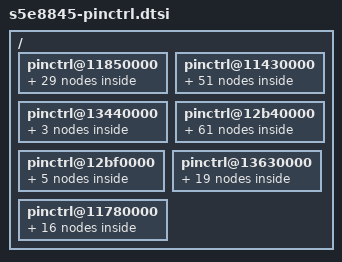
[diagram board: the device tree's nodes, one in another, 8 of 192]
/*
 * Samsung's S5E8845 SoC pin-mux and pin-config device tree source
 *
 * Copyright (c) 2023 Samsung Electronics Co., Ltd.
 *		http://www.samsung.com
 *
 * Samsung's S5E8845 SoC pin-mux and pin-config options are listed as device
 * tree nodes are listed in this file.
 *
 * This program is free software; you can redistribute it and/or modify
 * it under the terms of the GNU General Public License version 2 as
 * published by the Free Software Foundation.
*/

/ {
	/* ALIVE */
	pinctrl@11850000 {
		gpa0: gpa0 {
			gpio-controller;
			#gpio-cells = <2>;

			interrupt-controller;
			#interrupt-cells = <2>;
			interrupt-parent = <&gic>;
			interrupts = <GIC_SPI INTREQ__ALIVE_EINT0 IRQ_TYPE_LEVEL_HIGH>,
					<GIC_SPI INTREQ__ALIVE_EINT1 IRQ_TYPE_LEVEL_HIGH>,
					<GIC_SPI INTREQ__ALIVE_EINT2 IRQ_TYPE_LEVEL_HIGH>,
					<GIC_SPI INTREQ__ALIVE_EINT3 IRQ_TYPE_LEVEL_HIGH>,
					<GIC_SPI INTREQ__ALIVE_EINT4 IRQ_TYPE_LEVEL_HIGH>,
					<GIC_SPI INTREQ__ALIVE_EINT5 IRQ_TYPE_LEVEL_HIGH>,
					<GIC_SPI INTREQ__ALIVE_EINT6 IRQ_TYPE_LEVEL_HIGH>,
					<GIC_SPI INTREQ__ALIVE_EINT7 IRQ_TYPE_LEVEL_HIGH>;
		};

		gpa1: gpa1 {
			gpio-controller;
			#gpio-cells = <2>;

			interrupt-controller;
			#interrupt-cells = <2>;
			interrupt-parent = <&gic>;
			interrupts = <GIC_SPI INTREQ__ALIVE_EINT8 IRQ_TYPE_LEVEL_HIGH>,
					<GIC_SPI INTREQ__ALIVE_EINT9 IRQ_TYPE_LEVEL_HIGH>,
					<GIC_SPI INTREQ__ALIVE_EINT10 IRQ_TYPE_LEVEL_HIGH>,
					<GIC_SPI INTREQ__ALIVE_EINT11 IRQ_TYPE_LEVEL_HIGH>,
					<GIC_SPI INTREQ__ALIVE_EINT12 IRQ_TYPE_LEVEL_HIGH>;

		};

		gpq0: gpq0 {
			gpio-controller;
			#gpio-cells = <2>;
		};

		gpq1: gpq1 {
			gpio-controller;
			#gpio-cells = <2>;
		};

		gpc0: gpc0 {
			gpio-controller;
			#gpio-cells = <2>;

			interrupt-controller;
			#interrupt-cells = <2>;
			interrupt-parent = <&gic>;
			interrupts = <GIC_SPI INTREQ__ALIVE_EXT_INTC0 IRQ_TYPE_LEVEL_HIGH>;
		};

		gpc1: gpc1 {
			gpio-controller;
			#gpio-cells = <2>;

			interrupt-controller;
			#interrupt-cells = <2>;
			interrupt-parent = <&gic>;
			interrupts = <GIC_SPI INTREQ__ALIVE_EXT_INTC1 IRQ_TYPE_LEVEL_HIGH>;
		};

		gpc2: gpc2 {
			gpio-controller;
			#gpio-cells = <2>;

			interrupt-controller;
			#interrupt-cells = <2>;
			interrupt-parent = <&gic>;
			interrupts = <GIC_SPI INTREQ__ALIVE_EXT_INTC2 IRQ_TYPE_LEVEL_HIGH>;
		};

		gpc3: gpc3 {
			gpio-controller;
			#gpio-cells = <2>;

			interrupt-controller;
			#interrupt-cells = <2>;
			interrupt-parent = <&gic>;
			interrupts = <GIC_SPI INTREQ__ALIVE_EXT_INTC3 IRQ_TYPE_LEVEL_HIGH>;
		};

		gpc4: gpc4 {
			gpio-controller;
			#gpio-cells = <2>;

			interrupt-controller;
			#interrupt-cells = <2>;
			interrupt-parent = <&gic>;
			interrupts = <GIC_SPI INTREQ__ALIVE_EXT_INTC4 IRQ_TYPE_LEVEL_HIGH>;
		};

		gpc5: gpc5 {
			gpio-controller;
			#gpio-cells = <2>;

			interrupt-controller;
			#interrupt-cells = <2>;
			interrupt-parent = <&gic>;
			interrupts = <GIC_SPI INTREQ__ALIVE_EXT_INTC5 IRQ_TYPE_LEVEL_HIGH>;
		};

		gpc6: gpc6 {
			gpio-controller;
			#gpio-cells = <2>;

			interrupt-controller;
			#interrupt-cells = <2>;
			interrupt-parent = <&gic>;
			interrupts = <GIC_SPI INTREQ__ALIVE_EXT_INTC6 IRQ_TYPE_LEVEL_HIGH>;
		};

		gpc7: gpc7 {
			gpio-controller;
			#gpio-cells = <2>;

			interrupt-controller;
			#interrupt-cells = <2>;
			interrupt-parent = <&gic>;
			interrupts = <GIC_SPI INTREQ__ALIVE_EXT_INTC7 IRQ_TYPE_LEVEL_HIGH>;
		};

		gpc8: gpc8 {
			gpio-controller;
			#gpio-cells = <2>;

			interrupt-controller;
			#interrupt-cells = <2>;
			interrupt-parent = <&gic>;
			interrupts = <GIC_SPI INTREQ__ALIVE_EXT_INTC8 IRQ_TYPE_LEVEL_HIGH>;
		};

		gpc9: gpc9 {
			gpio-controller;
			#gpio-cells = <2>;

			interrupt-controller;
			#interrupt-cells = <2>;
			interrupt-parent = <&gic>;
			interrupts = <GIC_SPI INTREQ__ALIVE_EXT_INTC9 IRQ_TYPE_LEVEL_HIGH>;
		};

		gpc10: gpc10 {
			gpio-controller;
			#gpio-cells = <2>;

			interrupt-controller;
			#interrupt-cells = <2>;
			interrupt-parent = <&gic>;
			interrupts = <GIC_SPI INTREQ__ALIVE_EXT_INTC10 IRQ_TYPE_LEVEL_HIGH>;
		};

		gpc11: gpc11 {
			gpio-controller;
			#gpio-cells = <2>;

			interrupt-controller;
			#interrupt-cells = <2>;
			interrupt-parent = <&gic>;
			interrupts = <GIC_SPI INTREQ__ALIVE_EXT_INTC11 IRQ_TYPE_LEVEL_HIGH>;
		};

		gpc12: gpc12 {
			gpio-controller;
			#gpio-cells = <2>;

			interrupt-controller;
			#interrupt-cells = <2>;
			interrupt-parent = <&gic>;
			interrupts = <GIC_SPI INTREQ__ALIVE_EXT_INTC12 IRQ_TYPE_LEVEL_HIGH>;
		};

		gpc13: gpc13 {
			gpio-controller;
			#gpio-cells = <2>;

			interrupt-controller;
			#interrupt-cells = <2>;
			interrupt-parent = <&gic>;
			interrupts = <GIC_SPI INTREQ__ALIVE_EXT_INTC13 IRQ_TYPE_LEVEL_HIGH>;
		};

		gpc14: gpc14 {
			gpio-controller;
			#gpio-cells = <2>;

			interrupt-controller;
			#interrupt-cells = <2>;
			interrupt-parent = <&gic>;
			interrupts = <GIC_SPI INTREQ__ALIVE_EXT_INTC14 IRQ_TYPE_LEVEL_HIGH>;
		};

		gpj0: gpj0 {
			gpio-controller;
			#gpio-cells = <2>;

			interrupt-controller;
			#interrupt-cells = <2>;
			interrupt-parent = <&gic>;
			interrupts = <GIC_SPI INTREQ__ALIVE_EXT_INTC15 IRQ_TYPE_LEVEL_HIGH>;
		};

		gpj1: gpj1 {
			gpio-controller;
			#gpio-cells = <2>;

			interrupt-controller;
			#interrupt-cells = <2>;
			interrupt-parent = <&gic>;
			interrupts = <GIC_SPI INTREQ__ALIVE_EXT_INTC16 IRQ_TYPE_LEVEL_HIGH>;
		};

		gpj2: gpj2 {
			gpio-controller;
			#gpio-cells = <2>;

			interrupt-controller;
			#interrupt-cells = <2>;
			interrupt-parent = <&gic>;
			interrupts = <GIC_SPI INTREQ__ALIVE_EXT_INTC17 IRQ_TYPE_LEVEL_HIGH>;
		};

		/* USI_ALIVE0  */
		hsi2c27_bus: hsi2c27-bus {
			samsung,pins = "gpc11-0", "gpc12-0";
			samsung,pin-function = <2>;
			samsung,pin-pud = <3>;
			samsung,pin-drv = <0>;
		};

		/* I2C_ALIVE0  */
		hsi2c28_bus: hsi2c28-bus {
			samsung,pins = "gpc13-0", "gpc14-0";
			samsung,pin-function = <3>;
			samsung,pin-pud = <3>;
			samsung,pin-drv = <0>;
		};

		/* USI_ALIVE0 */
		spi14_bus: spi14-bus {
			samsung,pins = "gpc13-0", "gpc12-0", "gpc11-0";
			samsung,pin-function = <2>;
			samsung,pin-pud = <0>;
			samsung,pin-drv = <0>;
		};

		spi14_cs: spi14-cs {
			samsung,pins = "gpc14-0";
			samsung,pin-function = <1>;
			samsung,pin-pud = <0>;
			samsung,pin-drv = <0>;
		};

		spi14_cs_func: spi14-cs-func {
			samsung,pins = "gpc14-0";
			samsung,pin-function = <2>;
			samsung,pin-pud = <0>;
			samsung,pin-drv = <0>;
		};

		/* ALIVE_UART_DBG */
		uart0_bus: uart0-bus {
			samsung,pins = "gpq0-0", "gpq0-1";
			samsung,pin-function = <2>;
			samsung,pin-pud = <3>;
		};

		 /* BLK_ALIVE_USI_ALIVE0 */
		uart15_bus_single: uart15-bus {
			samsung,pins = "gpc11-0", "gpc12-0", "gpc13-0", "gpc14-0";
			samsung,pin-function = <2>;
			samsung,pin-pud = <0>;
		};
	};

	/* CMGP */
	pinctrl@11430000{
		gpm0: gpm0 {
			gpio-controller;
			#gpio-cells = <2>;

			interrupt-controller;
			#interrupt-cells = <2>;
			interrupt-parent = <&gic>;
			interrupts = <GIC_SPI INTREQ__EXT_INTM00 IRQ_TYPE_LEVEL_HIGH>;
		};

		gpm1: gpm1 {
			gpio-controller;
			#gpio-cells = <2>;

			interrupt-controller;
			#interrupt-cells = <2>;
			interrupt-parent = <&gic>;
			interrupts = <GIC_SPI INTREQ__EXT_INTM01 IRQ_TYPE_LEVEL_HIGH>;
		};

		gpm2: gpm2 {
			gpio-controller;
			#gpio-cells = <2>;

			interrupt-controller;
			#interrupt-cells = <2>;
			interrupt-parent = <&gic>;
			interrupts = <GIC_SPI INTREQ__EXT_INTM02 IRQ_TYPE_LEVEL_HIGH>;
		};

		gpm3: gpm3 {
			gpio-controller;
			#gpio-cells = <2>;

			interrupt-controller;
			#interrupt-cells = <2>;
			interrupt-parent = <&gic>;
			interrupts = <GIC_SPI INTREQ__EXT_INTM03 IRQ_TYPE_LEVEL_HIGH>;
		};

		gpm4: gpm4 {
			gpio-controller;
			#gpio-cells = <2>;

			interrupt-controller;
			#interrupt-cells = <2>;
			interrupt-parent = <&gic>;
			interrupts = <GIC_SPI INTREQ__EXT_INTM04 IRQ_TYPE_LEVEL_HIGH>;
		};

		gpm5: gpm5 {
			gpio-controller;
			#gpio-cells = <2>;

			interrupt-controller;
			#interrupt-cells = <2>;
			interrupt-parent = <&gic>;
			interrupts = <GIC_SPI INTREQ__EXT_INTM05 IRQ_TYPE_LEVEL_HIGH>;
		};

		gpm6: gpm6 {
			gpio-controller;
			#gpio-cells = <2>;

			interrupt-controller;
			#interrupt-cells = <2>;
			interrupt-parent = <&gic>;
			interrupts = <GIC_SPI INTREQ__EXT_INTM06 IRQ_TYPE_LEVEL_HIGH>;
		};

		gpm7: gpm7 {
			gpio-controller;
			#gpio-cells = <2>;

			interrupt-controller;
			#interrupt-cells = <2>;
			interrupt-parent = <&gic>;
			interrupts = <GIC_SPI INTREQ__EXT_INTM07 IRQ_TYPE_LEVEL_HIGH>;
		};

		gpm8: gpm8 {
			gpio-controller;
			#gpio-cells = <2>;

			interrupt-controller;
			#interrupt-cells = <2>;
			interrupt-parent = <&gic>;
			interrupts = <GIC_SPI INTREQ__EXT_INTM08 IRQ_TYPE_LEVEL_HIGH>;
		};

		gpm9: gpm9 {
			gpio-controller;
			#gpio-cells = <2>;

			interrupt-controller;
			#interrupt-cells = <2>;
			interrupt-parent = <&gic>;
			interrupts = <GIC_SPI INTREQ__EXT_INTM09 IRQ_TYPE_LEVEL_HIGH>;
		};

		gpm10: gpm10 {
			gpio-controller;
			#gpio-cells = <2>;

			interrupt-controller;
			#interrupt-cells = <2>;
			interrupt-parent = <&gic>;
			interrupts = <GIC_SPI INTREQ__EXT_INTM10 IRQ_TYPE_LEVEL_HIGH>;
		};

		gpm11: gpm11 {
			gpio-controller;
			#gpio-cells = <2>;

			interrupt-controller;
			#interrupt-cells = <2>;
			interrupt-parent = <&gic>;
			interrupts = <GIC_SPI INTREQ__EXT_INTM11 IRQ_TYPE_LEVEL_HIGH>;
		};

		gpm12: gpm12 {
			gpio-controller;
			#gpio-cells = <2>;

			interrupt-controller;
			#interrupt-cells = <2>;
			interrupt-parent = <&gic>;
			interrupts = <GIC_SPI INTREQ__EXT_INTM12 IRQ_TYPE_LEVEL_HIGH>;
		};

		gpm13: gpm13 {
			gpio-controller;
			#gpio-cells = <2>;

			interrupt-controller;
			#interrupt-cells = <2>;
			interrupt-parent = <&gic>;
			interrupts = <GIC_SPI INTREQ__EXT_INTM13 IRQ_TYPE_LEVEL_HIGH>;
		};

		gpm14: gpm14 {
			gpio-controller;
			#gpio-cells = <2>;

			interrupt-controller;
			#interrupt-cells = <2>;
			interrupt-parent = <&gic>;
			interrupts = <GIC_SPI INTREQ__EXT_INTM14 IRQ_TYPE_LEVEL_HIGH>;
		};

		gpm15: gpm15 {
			gpio-controller;
			#gpio-cells = <2>;

			interrupt-controller;
			#interrupt-cells = <2>;
			interrupt-parent = <&gic>;
			interrupts = <GIC_SPI INTREQ__EXT_INTM15 IRQ_TYPE_LEVEL_HIGH>;
		};

		gpm16: gpm16 {
			gpio-controller;
			#gpio-cells = <2>;

			interrupt-controller;
			#interrupt-cells = <2>;
			interrupt-parent = <&gic>;
			interrupts = <GIC_SPI INTREQ__EXT_INTM16 IRQ_TYPE_LEVEL_HIGH>;
		};

		gpm17: gpm17 {
			gpio-controller;
			#gpio-cells = <2>;

			interrupt-controller;
			#interrupt-cells = <2>;
			interrupt-parent = <&gic>;
			interrupts = <GIC_SPI INTREQ__EXT_INTM17 IRQ_TYPE_LEVEL_HIGH>;
		};

		gpm18: gpm18 {
			gpio-controller;
			#gpio-cells = <2>;

			interrupt-controller;
			#interrupt-cells = <2>;
			interrupt-parent = <&gic>;
			interrupts = <GIC_SPI INTREQ__EXT_INTM18 IRQ_TYPE_LEVEL_HIGH>;
		};

		gpm19: gpm19 {
			gpio-controller;
			#gpio-cells = <2>;

			interrupt-controller;
			#interrupt-cells = <2>;
			interrupt-parent = <&gic>;
			interrupts = <GIC_SPI INTREQ__EXT_INTM19 IRQ_TYPE_LEVEL_HIGH>;
		};

		gpm20: gpm20 {
			gpio-controller;
			#gpio-cells = <2>;

			interrupt-controller;
			#interrupt-cells = <2>;
			interrupt-parent = <&gic>;
			interrupts = <GIC_SPI INTREQ__EXT_INTM20 IRQ_TYPE_LEVEL_HIGH>;
		};

		/* USI_CMGP0 */
		hsi2c13_bus: hsi2c13-bus {
			samsung,pins = "gpm0-0", "gpm1-0";
			samsung,pin-function = <2>;
			samsung,pin-pud = <3>;
			samsung,pin-drv = <0>;
		};

		/* I2C_CMGP0 */
		hsi2c14_bus: hsi2c14-bus {
			samsung,pins = "gpm2-0", "gpm3-0";
			samsung,pin-function = <3>;
			samsung,pin-pud = <3>;
			samsung,pin-drv = <0>;
		};

		/* USI_CMGP1 */
		hsi2c15_bus: hsi2c15-bus {
			samsung,pins = "gpm4-0", "gpm5-0";
			samsung,pin-function = <2>;
			samsung,pin-pud = <3>;
			samsung,pin-drv = <0>;
		};

		/* I2C_CMGP1 */
		hsi2c16_bus: hsi2c16-bus {
			samsung,pins = "gpm6-0", "gpm7-0";
			samsung,pin-function = <3>;
			samsung,pin-pud = <3>;
			samsung,pin-drv = <0>;
		};

		/* USI_CMGP2 */
		hsi2c17_bus: hsi2c17-bus {
			samsung,pins = "gpm8-0", "gpm9-0";
			samsung,pin-function = <2>;
			samsung,pin-pud = <3>;
			samsung,pin-drv = <0>;
		};

		/* I2C_CMGP2 */
		hsi2c18_bus: hsi2c18-bus {
			samsung,pins = "gpm10-0", "gpm11-0";
			samsung,pin-function = <3>;
			samsung,pin-pud = <3>;
			samsung,pin-drv = <0>;
		};

		/* USI_CMGP3 */
		hsi2c19_bus: hsi2c19-bus {
			samsung,pins = "gpm13-0", "gpm14-0";
			samsung,pin-function = <2>;
			samsung,pin-pud = <3>;
			samsung,pin-drv = <0>;
		};

		/* I2C_CMGP3 */
		hsi2c20_bus: hsi2c20-bus {
			samsung,pins = "gpm15-0", "gpm16-0";
			samsung,pin-function = <3>;
			samsung,pin-pud = <3>;
			samsung,pin-drv = <0>;
		};

		/* USI_CMGP4 */
		hsi2c21_bus: hsi2c21-bus {
			samsung,pins = "gpm17-0", "gpm18-0";
			samsung,pin-function = <2>;
			samsung,pin-pud = <3>;
			samsung,pin-drv = <0>;
		};

		/* I2C_CMGP4 */
		hsi2c22_bus: hsi2c22-bus {
			samsung,pins = "gpm19-0", "gpm20-0";
			samsung,pin-function = <3>;
			samsung,pin-pud = <3>;
			samsung,pin-drv = <0>;
		};

		/* CMGP_USI0 */
		spi7_bus: spi7-bus {
			samsung,pins = "gpm2-0", "gpm1-0", "gpm0-0";
			samsung,pin-function = <2>;
			samsung,pin-pud = <0>;
			samsung,pin-drv = <0>;
		};

		spi7_cs: spi7-cs {
			samsung,pins = "gpm3-0";
			samsung,pin-function = <1>;
			samsung,pin-pud = <0>;
			samsung,pin-drv = <0>;
		};

		spi7_cs_func: spi7-cs-func {
			samsung,pins = "gpm3-0";
			samsung,pin-function = <2>;
			samsung,pin-pud = <0>;
			samsung,pin-drv = <0>;
		};

		/* CMGP_USI1 */
		spi8_bus: spi8-bus {
			samsung,pins = "gpm6-0", "gpm5-0", "gpm4-0";
			samsung,pin-function = <2>;
			samsung,pin-pud = <0>;
			samsung,pin-drv = <0>;
		};

		spi8_cs: spi8-cs {
			samsung,pins = "gpm7-0";
			samsung,pin-function = <1>;
			samsung,pin-pud = <0>;
			samsung,pin-drv = <0>;
		};

		spi8_cs_func: spi8-cs-func {
			samsung,pins = "gpm7-0";
			samsung,pin-function = <2>;
			samsung,pin-pud = <0>;
			samsung,pin-drv = <0>;
		};

		/* CMGP_USI2 */
		spi9_bus: spi9-bus {
			samsung,pins = "gpm10-0", "gpm9-0", "gpm8-0";
			samsung,pin-function = <2>;
			samsung,pin-pud = <0>;
			samsung,pin-drv = <0>;
		};

		spi9_cs: spi9-cs {
			samsung,pins = "gpm11-0";
			samsung,pin-function = <1>;
			samsung,pin-pud = <0>;
			samsung,pin-drv = <0>;
		};

		spi9_cs_func: spi9-cs-func {
			samsung,pins = "gpm11-0";
			samsung,pin-function = <2>;
			samsung,pin-pud = <0>;
			samsung,pin-drv = <0>;
		};

		/* CMGP_USI3 */
		spi10_bus: spi10-bus {
			samsung,pins = "gpm15-0", "gpm14-0", "gpm13-0";
			samsung,pin-function = <2>;
			samsung,pin-pud = <0>;
			samsung,pin-drv = <0>;
		};

		spi10_cs: spi10-cs {
			samsung,pins = "gpm16-0";
			samsung,pin-function = <1>;
			samsung,pin-pud = <0>;
			samsung,pin-drv = <0>;
		};

		spi10_cs_func: spi10-cs-func {
			samsung,pins = "gpm16-0";
			samsung,pin-function = <2>;
			samsung,pin-pud = <0>;
			samsung,pin-drv = <0>;
		};

		/* CMGP_USI4 */
		spi11_bus: spi11-bus {
			samsung,pins = "gpm19-0", "gpm18-0", "gpm17-0";
			samsung,pin-function = <2>;
			samsung,pin-pud = <0>;
			samsung,pin-drv = <0>;
		};

		spi11_cs: spi11-cs {
			samsung,pins = "gpm20-0";
			samsung,pin-function = <1>;
			samsung,pin-pud = <0>;
			samsung,pin-drv = <0>;
		};

		spi11_cs_func: spi11-cs-func {
			samsung,pins = "gpm20-0";
			samsung,pin-function = <2>;
			samsung,pin-pud = <0>;
			samsung,pin-drv = <0>;
		};

		/* CMGP_USI00_UART */
		uart8_bus_single: uart8-bus {
			samsung,pins = "gpm0-0", "gpm1-0", "gpm2-0", "gpm3-0";
			samsung,pin-function = <2>;
			samsung,pin-pud = <0>;
		};

		/* CMGP_USI01_UART */
		uart9_bus_single: uart9-bus {
			samsung,pins = "gpm4-0", "gpm5-0", "gpm6-0", "gpm7-0";
			samsung,pin-function = <2>;
			samsung,pin-pud = <0>;
		};

		/* CMGP_USI02_UART */
		uart10_bus_single: uart10-bus {
			samsung,pins = "gpm8-0", "gpm9-0", "gpm10-0", "gpm11-0";
			samsung,pin-function = <2>;
			samsung,pin-pud = <0>;
		};

		/* CMGP_USI03_UART */
		uart11_bus_single: uart11-bus {
			samsung,pins = "gpm13-0", "gpm14-0", "gpm15-0", "gpm16-0";
			samsung,pin-function = <2>;
			samsung,pin-pud = <0>;
		};

		/* CMGP_USI04_UART */
		uart12_bus_single: uart12-bus {
			samsung,pins = "gpm17-0", "gpm18-0", "gpm19-0", "gpm20-0";
			samsung,pin-function = <2>;
			samsung,pin-pud = <0>;
		};
	};

	/* HSI_UFS */
	pinctrl@13440000 {
		gpf3: gpf3 {
			gpio-controller;
			#gpio-cells = <2>;

			interrupt-controller;
			#interrupt-cells = <2>;
		};

		ufs_rst_n: ufs-rst-n {
			samsung,pins = "gpf3-1";
			samsung,pin-function = <3>;
			samsung,pin-pud = <0>;
			samsung,pin-con-pdn = <3>;
			samsung,pin-pud-pdn = <0>;
		};

		ufs_refclk_out: ufs-refclk-out {
			samsung,pins = "gpf3-0";
			samsung,pin-function = <3>;
			samsung,pin-pud = <0>;
			samsung,pin-con-pdn = <3>;
			samsung,pin-drv = <1>;
			samsung,pin-pud-pdn = <0>;
		};
	};

	/* PERIC*/
	pinctrl@12b40000 {
		gpp0: gpp0 {
			gpio-controller;
			#gpio-cells = <2>;

			interrupt-controller;
			#interrupt-cells = <2>;
		};

		gpp1: gpp1 {
			gpio-controller;
			#gpio-cells = <2>;

			interrupt-controller;
			#interrupt-cells = <2>;
		};

		gpp2: gpp2 {
			gpio-controller;
			#gpio-cells = <2>;

			interrupt-controller;
			#interrupt-cells = <2>;
		};

		gpg0: gpg0 {
			gpio-controller;
			#gpio-cells = <2>;

			interrupt-controller;
			#interrupt-cells = <2>;
		};

		gpg1: gpg1 {
			gpio-controller;
			#gpio-cells = <2>;

			interrupt-controller;
			#interrupt-cells = <2>;
		};

		gpb0: gpb0 {
			gpio-controller;
			#gpio-cells = <2>;

			interrupt-controller;
			#interrupt-cells = <2>;
		};

		gpb1: gpb1 {
			gpio-controller;
			#gpio-cells = <2>;

			interrupt-controller;
			#interrupt-cells = <2>;
		};

		aud_i2s0_bus:aud-i2s0-bus {
			samsung,pins = "gpb0-0", "gpb0-1", "gpb0-2", "gpb0-3";
			samsung,pin-function = <2>;
			samsung,pin-pud = <0>;
		};

		aud_i2s0_idle:aud-i2s0-idle {
			samsung,pins = "gpb0-0", "gpb0-1", "gpb0-2", "gpb0-3";
			samsung,pin-function = <0>;
			samsung,pin-pud = <1>;
		};

		aud_i2s1_bus:aud-i2s1-bus {
			samsung,pins = "gpb1-0", "gpb1-1", "gpb1-2", "gpb1-3";
			samsung,pin-function = <2>;
			samsung,pin-pud = <0>;
		};

		aud_i2s1_idle:aud-i2s1-idle {
			samsung,pins = "gpb1-0", "gpb1-1", "gpb1-2", "gpb1-3";
			samsung,pin-function = <0>;
			samsung,pin-pud = <1>;
		};

		aud_codec_mclk:aud-codec-mclk {
			samsung,pins = "gpb0-4";
			samsung,pin-function = <2>;
			samsung,pin-pud = <1>;
		};

		aud_codec_mclk_idle:aud-codec-mclk-idle {
			samsung,pins = "gpb0-4";
			samsung,pin-function = <0>;
			samsung,pin-pud = <1>;
		};

		/* PERIC_USI00_USI */
		hsi2c0_bus: hsi2c0-bus {
			samsung,pins = "gpp0-0", "gpp0-1";
			samsung,pin-function = <2>;
			samsung,pin-pud = <3>;
			samsung,pin-drv = <0>;
		};

		/* PERIC_USI00_I2C */
		hsi2c1_bus: hsi2c1-bus {
			samsung,pins = "gpp0-2", "gpp0-3";
			samsung,pin-function = <3>;
			samsung,pin-pud = <3>;
			samsung,pin-drv = <0>;
		};

		/* PERIC_USI01_USI */
		hsi2c2_bus: hsi2c2-bus {
			samsung,pins = "gpp0-4", "gpp0-5";
			samsung,pin-function = <2>;
			samsung,pin-pud = <3>;
			samsung,pin-drv = <0>;
		};

		/* PERIC_USI01_I2C */
		hsi2c3_bus: hsi2c3-bus {
			samsung,pins = "gpp0-6", "gpp0-7";
			samsung,pin-function = <3>;
			samsung,pin-pud = <3>;
			samsung,pin-drv = <0>;
		};

		/* PERIC_USI02_USI */
		hsi2c4_bus: hsi2c4-bus {
			samsung,pins = "gpp1-0", "gpp1-1";
			samsung,pin-function = <2>;
			samsung,pin-pud = <3>;
			samsung,pin-drv = <0>;
		};

		/* PERIC_USI02_I2C */
		hsi2c5_bus: hsi2c5-bus {
			samsung,pins = "gpp1-2", "gpp1-3";
			samsung,pin-function = <3>;
			samsung,pin-pud = <3>;
			samsung,pin-drv = <0>;
		};

		/* PERIC_USI03_USI */
		hsi2c6_bus: hsi2c6-bus {
			samsung,pins = "gpp1-4", "gpp1-5";
			samsung,pin-function = <2>;
			samsung,pin-pud = <3>;
			samsung,pin-drv = <0>;
		};

		/* PERIC_USI03_I2C */
		hsi2c7_bus: hsi2c7-bus {
			samsung,pins = "gpp1-6", "gpp1-7";
			samsung,pin-function = <3>;
			samsung,pin-pud = <3>;
			samsung,pin-drv = <0>;
		};

		/* PERIC_USI04_USI */
		hsi2c8_bus: hsi2c8-bus {
			samsung,pins = "gpp2-0", "gpp2-1";
			samsung,pin-function = <2>;
			samsung,pin-pud = <3>;
			samsung,pin-drv = <0>;
		};

		/* PERIC_USI04_I2C */
		hsi2c9_bus: hsi2c9-bus {
			samsung,pins = "gpp2-2", "gpp2-3";
			samsung,pin-function = <3>;
			samsung,pin-pud = <3>;
			samsung,pin-drv = <0>;
		};

		/* PERIC_USI05_I2C */
		hsi2c10_bus: hsi2c10-bus {
			samsung,pins = "gpp2-4", "gpp2-5";
			samsung,pin-function = <2>;
			samsung,pin-pud = <3>;
			samsung,pin-drv = <0>;
		};

		/* PERIC_USI09_USI_OIS */
		hsi2c11_bus: hsi2c11-bus {
			samsung,pins = "gpp1-4", "gpp1-5";
			samsung,pin-function = <4>;
			samsung,pin-pud = <3>;
			samsung,pin-drv = <0>;
		};

		/* PERIC_USI10_USI_OIS */
		hsi2c12_bus: hsi2c12-bus {
			samsung,pins = "gpp2-0", "gpp2-1";
			samsung,pin-function = <4>;
			samsung,pin-pud = <3>;
			samsung,pin-drv = <0>;
		};

		/* PERIC_USI00_SPI */
		spi0_bus: spi0-bus {
			samsung,pins = "gpp0-2", "gpp0-1", "gpp0-0";
			samsung,pin-function = <2>;
			samsung,pin-pud = <0>;
			samsung,pin-drv = <0>;
		};

		spi0_cs: spi0-cs {
			samsung,pins = "gpp0-3";
			samsung,pin-function = <1>;
			samsung,pin-pud = <0>;
			samsung,pin-drv = <0>;
		};

		spi0_cs_func: spi0-cs-func {
			samsung,pins = "gpp0-3";
			samsung,pin-function = <2>;
			samsung,pin-pud = <0>;
			samsung,pin-drv = <0>;
		};

		/* PERIC_USI01_SPI */
		spi1_bus: spi1-bus {
			samsung,pins = "gpp0-6", "gpp0-5", "gpp0-4";
			samsung,pin-function = <2>;
			samsung,pin-pud = <0>;
			samsung,pin-drv = <0>;
		};

		spi1_cs: spi1-cs {
			samsung,pins = "gpp0-7";
			samsung,pin-function = <1>;
			samsung,pin-pud = <0>;
			samsung,pin-drv = <0>;
		};

		spi1_cs_func: spi1-cs-func {
			samsung,pins = "gpp0-7";
			samsung,pin-function = <2>;
			samsung,pin-pud = <0>;
			samsung,pin-drv = <0>;
		};

		/* PERIC_USI02_SPI */
		spi2_bus: spi2-bus {
			samsung,pins = "gpp1-2", "gpp1-1", "gpp1-0";
			samsung,pin-function = <2>;
			samsung,pin-pud = <0>;
			samsung,pin-drv = <0>;
		};

		spi2_cs: spi2-cs {
			samsung,pins = "gpp1-3";
			samsung,pin-function = <1>;
			samsung,pin-pud = <0>;
			samsung,pin-drv = <0>;
		};

		spi2_cs_func: spi2-cs-func {
			samsung,pins = "gpp1-3";
			samsung,pin-function = <2>;
			samsung,pin-pud = <0>;
			samsung,pin-drv = <0>;
		};

		/* PERIC_USI03_SPI */
		spi3_bus: spi3-bus {
			samsung,pins = "gpp1-6", "gpp1-5", "gpp1-4";
			samsung,pin-function = <2>;
			samsung,pin-pud = <0>;
			samsung,pin-drv = <0>;
		};

		spi3_cs: spi3-cs {
			samsung,pins = "gpp1-7";
			samsung,pin-function = <1>;
			samsung,pin-pud = <0>;
			samsung,pin-drv = <0>;
		};

		spi3_cs_func: spi3-cs-func {
			samsung,pins = "gpp1-7";
			samsung,pin-function = <2>;
			samsung,pin-pud = <0>;
			samsung,pin-drv = <0>;
		};

		/* PERIC_USI04_SPI */
		spi4_bus: spi4-bus {
			samsung,pins = "gpp2-2", "gpp2-1", "gpp2-0";
			samsung,pin-function = <2>;
			samsung,pin-pud = <0>;
			samsung,pin-drv = <0>;
		};

		spi4_cs: spi4-cs {
			samsung,pins = "gpp2-3";
			samsung,pin-function = <1>;
			samsung,pin-pud = <0>;
			samsung,pin-drv = <0>;
		};

		spi4_cs_func: spi4-cs-func {
			samsung,pins = "gpp2-3";
			samsung,pin-function = <2>;
			samsung,pin-pud = <0>;
			samsung,pin-drv = <0>;
		};

		/* PERIC_USI09_OIS_SPI */
		spi5_bus: spi5-bus {
			samsung,pins = "gpp1-6", "gpp1-5", "gpp1-4";
			samsung,pin-function = <4>;
			samsung,pin-pud = <0>;
			samsung,pin-drv = <0>;
		};

		spi5_cs: spi5-cs {
			samsung,pins = "gpp1-7";
			samsung,pin-function = <1>;
			samsung,pin-pud = <0>;
			samsung,pin-drv = <0>;
		};

		spi5_cs_func: spi5-cs-func {
			samsung,pins = "gpp1-7";
			samsung,pin-function = <4>;
			samsung,pin-pud = <0>;
			samsung,pin-drv = <0>;
		};

		/* PERIC_USI10_OIS_SPI */
		spi6_bus: spi6-bus {
			samsung,pins = "gpp2-2", "gpp2-1", "gpp2-0";
			samsung,pin-function = <4>;
			samsung,pin-pud = <0>;
			samsung,pin-drv = <0>;
		};

		spi6_cs: spi6-cs {
			samsung,pins = "gpp2-3";
			samsung,pin-function = <1>;
			samsung,pin-pud = <0>;
			samsung,pin-drv = <0>;
		};

		spi6_cs_func: spi6-cs-func {
			samsung,pins = "gpp2-3";
			samsung,pin-function = <4>;
			samsung,pin-pud = <0>;
			samsung,pin-drv = <0>;
		};

		/* PERIC_USI00_UART */
		uart1_bus_single: uart1-bus {
			samsung,pins = "gpp0-0", "gpp0-1", "gpp0-2", "gpp0-3";
			samsung,pin-function = <2>;
			samsung,pin-pud = <0>;
		};

		/* PERIC_USI01_UART */
		uart2_bus_single: uart2-bus {
			samsung,pins = "gpp0-4", "gpp0-5", "gpp0-6", "gpp0-7";
			samsung,pin-function = <2>;
			samsung,pin-pud = <0>;
		};

		/* PERIC_USI02_UART */
		uart3_bus_single: uart3-bus {
			samsung,pins = "gpp1-0", "gpp1-1", "gpp1-2", "gpp1-3";
			samsung,pin-function = <2>;
			samsung,pin-pud = <0>;
		};

		/* PERIC_USI03_UART */
		uart4_bus_single: uart4-bus {
			samsung,pins = "gpp1-4", "gpp1-5", "gpp1-6", "gpp1-7";
			samsung,pin-function = <2>;
			samsung,pin-pud = <0>;
		};

		/* PERIC_USI04_UART */
		uart5_bus_single: uart5-bus {
			samsung,pins = "gpp2-0", "gpp2-1", "gpp2-2", "gpp2-3";
			samsung,pin-function = <2>;
			samsung,pin-pud = <0>;
		};

		/* PERIC_USI09_OIS_UART */
		uart6_bus_single: uart6-bus {
			samsung,pins = "gpp1-4", "gpp1-5", "gpp1-6", "gpp1-7";
			samsung,pin-function = <4>;
			samsung,pin-pud = <0>;
		};

		/* PERIC_USI10_OIS_UART */
		uart7_bus_single: uart7-bus {
			samsung,pins = "gpp2-0", "gpp2-1", "gpp2-2", "gpp2-3";
			samsung,pin-function = <4>;
			samsung,pin-pud = <0>;
		};

		sensor_mclk0_out: sensor-mclk0-out {
			samsung,pins = "gpg0-1";        /* CIS_CLK0 : WIDE_TELECAM_MCLK */
			samsung,pin-function = <1>;
			samsung,pin-pud = <1>;
			samsung,pin-drv = <0>;
		};

		sensor_mclk1_out: sensor-mclk1-out {
			samsung,pins = "gpg0-2";        /* CIS_CLK1 : UWCAM_MCLK */
			samsung,pin-function = <1>;
			samsung,pin-pud = <1>;
			samsung,pin-drv = <0>;
		};

		sensor_mclk2_out: sensor-mclk2-out {
			samsung,pins = "gpg0-3";        /* CIS_CLK2 : VTCAM_MCLK */
			samsung,pin-function = <1>;
			samsung,pin-pud = <1>;
			samsung,pin-drv = <0>;
		};

		sensor_mclk0_fn: sensor-mclk0-fn {
			samsung,pins = "gpg0-1";        /* CIS_CLK0 : WIDE_TELECAM_MCLK */
			samsung,pin-function = <2>;
			samsung,pin-pud = <0>;
			samsung,pin-drv = <0>;
		};

		sensor_mclk1_fn: sensor-mclk1-fn {
			samsung,pins = "gpg0-2";        /* CIS_CLK1 : UWCAM_MCLK */
			samsung,pin-function = <2>;
			samsung,pin-pud = <0>;
			samsung,pin-drv = <0>;
		};

		sensor_mclk2_fn: sensor-mclk2-fn {
			samsung,pins = "gpg0-3";        /* CIS_CLK2 : VTCAM_MCLK */
			samsung,pin-function = <2>;
			samsung,pin-pud = <0>;
			samsung,pin-drv = <0>;
		};

		fm_spdy_default: fm-spdy-default {
			samsung,pins = "gpb0-5";
			samsung,pin-function = <0>;
			samsung,pin-pud = <1>;

		};
	};

	/* PERICMMC */
	pinctrl@12bf0000 {
		gpf2: gpf2 {
			gpio-controller;
			#gpio-cells = <2>;

			interrupt-controller;
			#interrupt-cells = <2>;
		};
		sd2_clk: sd2-clk {
			samsung,pins = "gpf2-0";
			samsung,pin-function = <2>;
			samsung,pin-pud = <0>;
			samsung,pin-drv = <5>;
			samsung,pin-con-pdn = <3>;
			samsung,pin-pud-pdn = <0>;
		};

		sd2_cmd: sd2-cmd {
			samsung,pins = "gpf2-1";
			samsung,pin-function = <2>;
			samsung,pin-pud = <0>;
			samsung,pin-drv = <5>;
			samsung,pin-con-pdn = <3>;
			samsung,pin-pud-pdn = <0>;
		};

		sd2_bus1: sd2-bus-width1 {
			samsung,pins = "gpf2-2";
			samsung,pin-function = <2>;
			samsung,pin-pud = <0>;
			samsung,pin-drv = <5>;
			samsung,pin-con-pdn = <3>;
			samsung,pin-pud-pdn = <0>;
		};

		sd2_bus4: sd2-bus-width4 {
			samsung,pins = "gpf2-3", "gpf2-4", "gpf2-5";
			samsung,pin-function = <2>;
			samsung,pin-pud = <0>;
			samsung,pin-drv = <5>;
			samsung,pin-con-pdn = <3>;
			samsung,pin-pud-pdn = <0>;
		};
	};

	/* GPIO USI */
	pinctrl@13630000 {
		gpp3: gpp3 {
			gpio-controller;
			#gpio-cells = <2>;

			interrupt-controller;
			#interrupt-cells = <2>;
		};

		gpp4: gpp4 {
			gpio-controller;
			#gpio-cells = <2>;

			interrupt-controller;
			#interrupt-cells = <2>;
		};

		gpg2: gpg2 {
			gpio-controller;
			#gpio-cells = <2>;

			interrupt-controller;
			#interrupt-cells = <2>;
		};

		gpg3: gpg3 {
			gpio-controller;
			#gpio-cells = <2>;

			interrupt-controller;
			#interrupt-cells = <2>;
		};

		decon_0_te_on: decon_0_te_on {
		        samsung,pins = "gpg3-0";
		        samsung,pin-function = <0xf>;
		};

		decon_0_te_off: decon_0_te_off {
		        samsung,pins = "gpg3-0";
		        samsung,pin-function = <0>;
		};

		/* USI_USI06 */
		hsi2c23_bus: hsi2c23-bus {
			samsung,pins = "gpp3-0", "gpp3-1";
			samsung,pin-function = <2>;
			samsung,pin-pud = <3>;
			samsung,pin-drv = <0>;
		};

		/* I2C_USI06 */
		hsi2c24_bus: hsi2c24-bus {
			samsung,pins = "gpp3-2", "gpp3-3";
			samsung,pin-function = <3>;
			samsung,pin-pud = <3>;
			samsung,pin-drv = <0>;
		};

		/* USI_USI07 */
		hsi2c25_bus: hsi2c25-bus {
			samsung,pins = "gpp3-4", "gpp3-5";
			samsung,pin-function = <2>;
			samsung,pin-pud = <3>;
			samsung,pin-drv = <0>;
		};

		/* I2C_USI07 */
		hsi2c26_bus: hsi2c26-bus {
			samsung,pins = "gpp3-6", "gpp3-7";
			samsung,pin-function = <3>;
			samsung,pin-pud = <3>;
			samsung,pin-drv = <0>;
		};

		/* I2C_USI08 */
		hsi2c29_bus: hsi2c29-bus {
			samsung,pins = "gpp4-0", "gpp4-1";
			samsung,pin-function = <2>;
			samsung,pin-pud = <3>;
			samsung,pin-drv = <0>;
		};

		/* USI_USI06 */
		spi12_bus: spi12-bus {
			samsung,pins = "gpp3-2", "gpp3-1", "gpp3-0";
			samsung,pin-function = <2>;
			samsung,pin-pud = <0>;
			samsung,pin-drv = <0>;
		};

		spi12_cs: spi12-cs {
			samsung,pins = "gpp3-3";
			samsung,pin-function = <1>;
			samsung,pin-pud = <0>;
			samsung,pin-drv = <0>;
		};

		spi12_cs_func: spi12-cs-func {
			samsung,pins = "gpp3-3";
			samsung,pin-function = <2>;
			samsung,pin-pud = <0>;
			samsung,pin-drv = <0>;
		};

		/* USI_USI07 */
		spi13_bus: spi13-bus {
			samsung,pins = "gpp3-6", "gpp3-5", "gpp3-4";
			samsung,pin-function = <2>;
			samsung,pin-pud = <0>;
			samsung,pin-drv = <0>;
		};

		spi13_cs: spi13-cs {
			samsung,pins = "gpp3-7";
			samsung,pin-function = <1>;
			samsung,pin-pud = <0>;
			samsung,pin-drv = <0>;
		};

		spi13_cs_func: spi13-cs-func {
			samsung,pins = "gpp3-7";
			samsung,pin-function = <2>;
			samsung,pin-pud = <0>;
			samsung,pin-drv = <0>;
		};

		/* USI_USI06_UART */
		uart13_bus_single: uart13-bus {
			samsung,pins = "gpp3-0", "gpp3-1", "gpp3-2", "gpp3-3";
			samsung,pin-function = <2>;
			samsung,pin-pud = <0>;
		};

		/* USI_USI07_UART */
		uart14_bus_single: uart14-bus {
			samsung,pins = "gpp3-4", "gpp3-5", "gpp3-6", "gpp3-7";
			samsung,pin-function = <2>;
			samsung,pin-pud = <0>;
		};
	};

	/* VTS */
	pinctrl@11780000 {
		gpv0: gpv0 {
			gpio-controller;
			#gpio-cells = <2>;

			interrupt-controller;
			#interrupt-cells = <2>;
		};

		dmic_bus_clk0: dmic-bus-clk0 {
			samsung,pins = "gpv0-2";
			samsung,pin-function = <2>;
			samsung,pin-pud = <1>;
			samsung,pin-con-pdn = <2>;
		};

		dmic_bus_clk0_idle: dmic-bus-clk0-idle {
			samsung,pins = "gpv0-2";
			samsung,pin-function = <0>;
			samsung,pin-pud = <0>;
			samsung,pin-con-pdn = <2>;
		};

		dmic_bus_clk1: dmic-bus-clk1 {
			samsung,pins = "gpv0-2";
			samsung,pin-function = <2>;
			samsung,pin-pud = <1>;
			samsung,pin-con-pdn = <2>;
		};

		dmic_bus_clk1_idle: dmic-bus-clk1-idle {
			samsung,pins = "gpv0-2";
			samsung,pin-function = <0>;
			samsung,pin-pud = <0>;
			samsung,pin-con-pdn = <2>;
		};

		dmic_bus_clk2: dmic-bus-clk2 {
			samsung,pins = "gpv0-3";
			samsung,pin-function = <2>;
			samsung,pin-pud = <1>;
			samsung,pin-con-pdn = <2>;
		};

		dmic_bus_clk2_idle: dmic-bus-clk2-idle {
			samsung,pins = "gpv0-3";
			samsung,pin-function = <0>;
			samsung,pin-pud = <0>;
			samsung,pin-con-pdn = <2>;
		};

		dmic_pdm0_bus: dmic-pdm0-bus {
			samsung,pins = "gpv0-0";
			samsung,pin-function = <2>;
			samsung,pin-pud = <1>;
			samsung,pin-con-pdn = <2>;
		};

		amic_pdm0_bus: amic-pdm0-bus {
			samsung,pins = "gpv0-0";
			samsung,pin-function = <2>;
			samsung,pin-pud = <1>;
			samsung,pin-con-pdn = <2>;
		};

		dmic_pdm0_idle: dmic-pdm0-idle {
			samsung,pins = "gpv0-0";
			samsung,pin-function = <0>;
			samsung,pin-pud = <0>;
			samsung,pin-con-pdn = <2>;
		};

		dmic_pdm1_bus: dmic-pdm1-bus {
			samsung,pins = "gpv0-0";
			samsung,pin-function = <2>;
			samsung,pin-pud = <1>;
			samsung,pin-con-pdn = <2>;
		};

		amic_pdm1_bus: amic-pdm1-bus {
			samsung,pins = "gpv0-0";
			samsung,pin-function = <2>;
			samsung,pin-pud = <1>;
			samsung,pin-con-pdn = <2>;
		};

		dmic_pdm1_idle: dmic-pdm1-idle {
			samsung,pins = "gpv0-0";
			samsung,pin-function = <0>;
			samsung,pin-pud = <0>;
			samsung,pin-con-pdn = <2>;
		};

		dmic_pdm2_bus: dmic-pdm2-bus {
			samsung,pins = "gpv0-1";
			samsung,pin-function = <2>;
			samsung,pin-pud = <1>;
			samsung,pin-con-pdn = <2>;
		};

		amic_pdm2_bus: amic-pdm2-bus {
			samsung,pins = "gpv0-1";
			samsung,pin-function = <2>;
			samsung,pin-pud = <1>;
			samsung,pin-con-pdn = <2>;
		};

		dmic_pdm2_idle: dmic-pdm2-idle {
			samsung,pins = "gpv0-1";
			samsung,pin-function = <0>;
			samsung,pin-pud = <0>;
			samsung,pin-con-pdn = <2>;
		};
	};
};
